# PIC32CZ5125CA70144 register map
Vendor: Microchip Technology; Series: PIC32CZCA70; File version: 0
CPU: CM7 r1p1, little endian, MPU, FPU, double-precision FPU, I-cache, D-cache, ITCM, DTCM, 3 interrupt priority bits, 74 interrupts
Registers are 32-bit, read-write, reset 0x0 unless marked. A register's access mark holds for its fields unless they carry their own. Offsets are from the block's base; [hi:lo] are bit positions; {n}, {i} and the like mark numbered series; 'fields as' and 'values as' point back to an identical list.

## SPI0 — Serial Peripheral Interface
Base 0x40008000; register names take the prefix SPI_
Same registers: SPI1 0x40058000
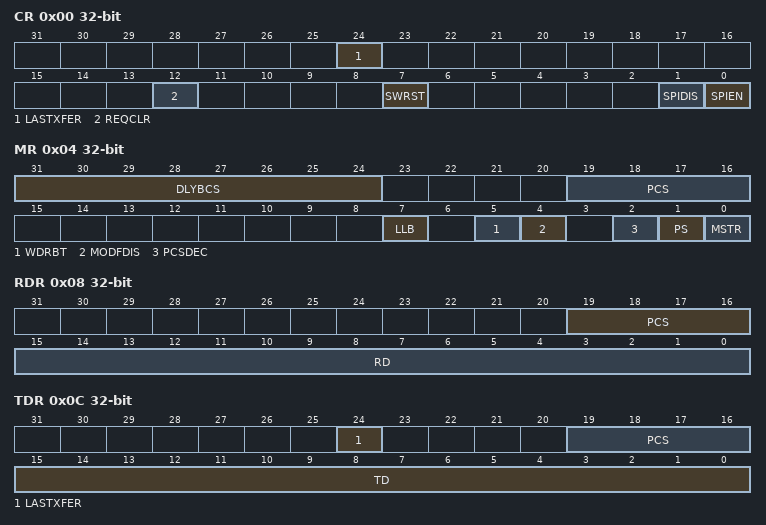
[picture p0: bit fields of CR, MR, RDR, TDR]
0x00 CR wo — Control Register
  [24] LASTXFER — Last Transfer
  [12] REQCLR — Request to Clear the Comparison Trigger
  [7] SWRST — SPI Software Reset
  [1] SPIDIS — SPI Disable
  [0] SPIEN — SPI Enable
0x04 MR — Mode Register
  [31:24] DLYBCS — Delay Between Chip Selects
  [19:16] PCS — Peripheral Chip Select
    14=NPCS0 (NPCS0 as Chip Select); 13=NPCS1 (NPCS1 as Chip Select); 11=NPCS2 (NPCS2 as Chip Select); 7=NPCS3 (NPCS3 as Chip Select)
  [7] LLB — Local Loopback Enable
  [5] WDRBT — Wait Data Read Before Transfer
  [4] MODFDIS — Mode Fault Detection
  [2] PCSDEC — Chip Select Decode
  [1] PS — Peripheral Select
  [0] MSTR — Master/Slave Mode
    1=MASTER; 0=SLAVE
0x08 RDR ro — Receive Data Register
  [19:16] PCS — Peripheral Chip Select
  [15:0] RD — Receive Data
0x0C TDR wo — Transmit Data Register
  [24] LASTXFER — Last Transfer
  [19:16] PCS — Peripheral Chip Select
    values as MR.PCS
  [15:0] TD — Transmit Data
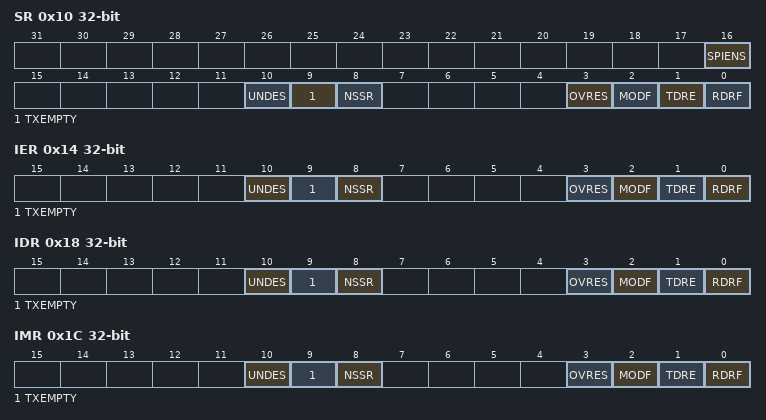
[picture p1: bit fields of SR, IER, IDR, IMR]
0x10 SR ro — Status Register
  [16] SPIENS — SPI Enable Status
  [10] UNDES — Underrun Error Status (Slave mode only) (cleared on read)
  [9] TXEMPTY — Transmission Registers Empty (cleared by writing SPI_TDR)
  [8] NSSR — NSS Rising (cleared on read)
  [3] OVRES — Overrun Error Status (cleared on read)
  [2] MODF — Mode Fault Error (cleared on read)
  [1] TDRE — Transmit Data Register Empty (cleared by writing SPI_TDR)
  [0] RDRF — Receive Data Register Full (cleared by reading SPI_RDR)
0x14 IER wo — Interrupt Enable Register
  [10] UNDES — Underrun Error Interrupt Enable
  [9] TXEMPTY — Transmission Registers Empty Enable
  [8] NSSR — NSS Rising Interrupt Enable
  [3] OVRES — Overrun Error Interrupt Enable
  [2] MODF — Mode Fault Error Interrupt Enable
  [1] TDRE — SPI Transmit Data Register Empty Interrupt Enable
  [0] RDRF — Receive Data Register Full Interrupt Enable
0x18 IDR wo — Interrupt Disable Register
  [10] UNDES — Underrun Error Interrupt Disable
  [9] TXEMPTY — Transmission Registers Empty Disable
  [8] NSSR — NSS Rising Interrupt Disable
  [3] OVRES — Overrun Error Interrupt Disable
  [2] MODF — Mode Fault Error Interrupt Disable
  [1] TDRE — SPI Transmit Data Register Empty Interrupt Disable
  [0] RDRF — Receive Data Register Full Interrupt Disable
0x1C IMR ro — Interrupt Mask Register
  [10] UNDES — Underrun Error Interrupt Mask
  [9] TXEMPTY — Transmission Registers Empty Mask
  [8] NSSR — NSS Rising Interrupt Mask
  [3] OVRES — Overrun Error Interrupt Mask
  [2] MODF — Mode Fault Error Interrupt Mask
  [1] TDRE — SPI Transmit Data Register Empty Interrupt Mask
  [0] RDRF — Receive Data Register Full Interrupt Mask
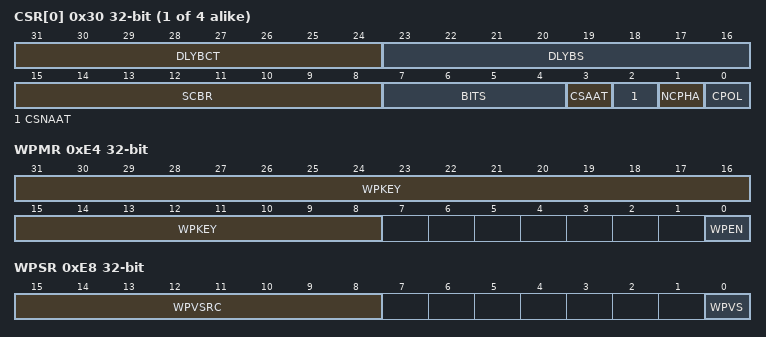
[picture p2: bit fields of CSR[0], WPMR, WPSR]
{0x30+4i} CSR[{i}] (i=0..3) — Chip Select Register
  [31:24] DLYBCT — Delay Between Consecutive Transfers
  [23:16] DLYBS — Delay Before SPCK
  [15:8] SCBR — Serial Clock Bit Rate
  [7:4] BITS — Bits Per Transfer
    {v}=_{v+8}_BIT ({v+8} bits for transfer) (v=0..8)
  [3] CSAAT — Chip Select Active After Transfer
  [2] CSNAAT — Chip Select Not Active After Transfer (Ignored if CSAAT = 1)
  [1] NCPHA — Clock Phase
    1=VALID_LEADING_EDGE (Data is valid on clock leading edge (NCPHA=1)); 0=VALID_TRAILING_EDGE (Data is valid on clock trailing edge (NCPHA=0))
  [0] CPOL — Clock Polarity
    0=IDLE_LOW (Clock is low when inactive (CPOL=0)); 1=IDLE_HIGH (Clock is high when inactive (CPOL=1))
0xE4 WPMR — Write Protection Mode Register
  [31:8] WPKEY — Write Protection Key
    0x535049=PASSWD (Writing any other value in this field aborts the write operation of the WPEN bit.Always reads as 0.)
  [0] WPEN — Write Protection Enable
0xE8 WPSR ro — Write Protection Status Register
  [15:8] WPVSRC — Write Protection Violation Source
  [0] WPVS — Write Protection Violation Status

## Notices in the file
Copyright (c) 2026 Microchip Technology Inc.
SPDX-License-Identifier: Apache-2.0
Licensed under the Apache License, Version 2.0 (the "License");
you may not use this file except in compliance with the License.
You may obtain a copy of the License at
http://www.apache.org/licenses/LICENSE-2.0
Unless required by applicable law or agreed to in writing, software
distributed under the License is distributed on an "AS IS" BASIS,
WITHOUT WARRANTIES OR CONDITIONS OF ANY KIND, either express or implied.
See the License for the specific language governing permissions and
limitations under the License.
